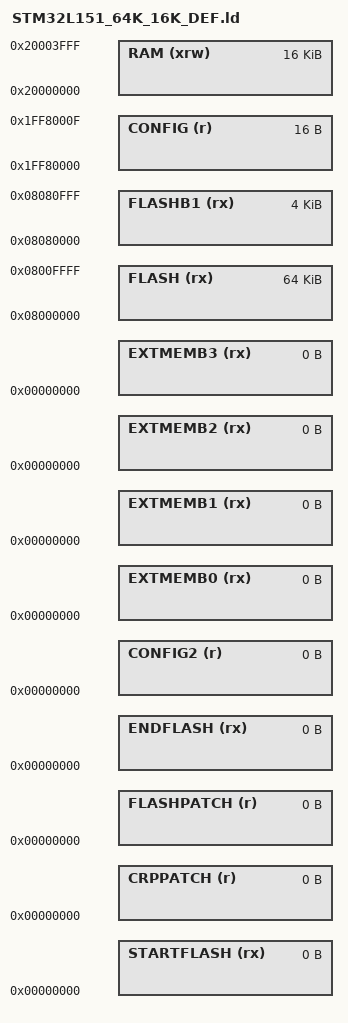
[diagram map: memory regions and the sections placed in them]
/*
Linker subscript for STM32 definitions with 64K Flash and 16K RAM
Copyright RAISONANCE 2007-2012
!!! This file is automatically generated by Ride !!!
Do not modify it, as it will be erased at every link.
You can use, copy and distribute this file freely, but without any waranty.
*/

/* Memory Spaces Definitions */

MEMORY
{
  RAM (xrw)       : ORIGIN = 0x20000000, LENGTH = 0x4000
  FLASH (rx)      : ORIGIN = 0x08000000, LENGTH = 0x10000
  STARTFLASH (rx) : ORIGIN = 0x0, LENGTH = 0x0
  CRPPATCH (r)    : ORIGIN = 0x0, LENGTH = 0
  FLASHPATCH (r)  : ORIGIN = 0x00000000, LENGTH = 0
  ENDFLASH (rx)   : ORIGIN = 0x00000000, LENGTH = 0
  FLASHB1  (rx)   : ORIGIN = 0x08080000, LENGTH = 0x1000
  CONFIG   (r)    : ORIGIN = 0x1FF80000, LENGTH = 0x10
  CONFIG2  (r)    : ORIGIN = 0x00000000, LENGTH = 0x0
  EXTMEMB0 (rx)   : ORIGIN = 0x00000000, LENGTH = 0
  EXTMEMB1 (rx)   : ORIGIN = 0x00000000, LENGTH = 0
  EXTMEMB2 (rx)   : ORIGIN = 0x00000000, LENGTH = 0
  EXTMEMB3 (rx)   : ORIGIN = 0x00000000, LENGTH = 0
}

/* higher address of the user mode stack */
_estack = 0x20004000;

